AUTOSAR XML (schema 4-2-1)
package /MICROSAR/Os_swc/DataTypes
  impl type TimeInMicrosecondsType: range raw 0..4294967295, implementation-data-type=uint32
  impl type CounterType: range raw 0..255, implementation-data-type=uint8, type-emitter=Os
package /MICROSAR/Os_swc/Interfaces
  client server interface Os_Service: is-service=true, service-kind=OPERATING-SYSTEM
    operation GetCounterValue: possible-error=[E_OK, E_OS_ID]  # This service reads the current count value of a counter (returning either the hardware timer ticks if counter is driven by hardware or the software ticks when user drives counter).
      arg Value: type=TimeInMicrosecondsType, direction=OUT
    operation GetElapsedValue: possible-error=[E_OK, E_OS_ID, E_OS_VALUE]  # This service gets the number of ticks between the current tick value and a previously read tick value.
      arg Value: type=TimeInMicrosecondsType, direction=INOUT
      arg ElapsedValue: type=TimeInMicrosecondsType, direction=OUT
    5 x error:
      E_OK: error-code=0
      E_OS_ACCESS: error-code=1
      E_OS_ID: error-code=3
      E_OS_STATE: error-code=7
      E_OS_VALUE: error-code=8
package /MICROSAR/Os_swc/ComponentTypes
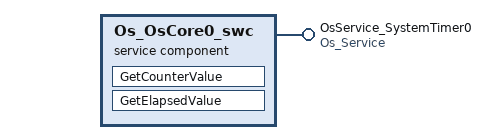
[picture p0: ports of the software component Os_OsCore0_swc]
  service sw component type Os_OsCore0_swc: category=SERVICE_COMPONENT
    provide port OsService_SystemTimer0: provided-interface=Os_Service
    behavior Os_OsCore0_swcInternalBehavior: handle-termination-and-restart=NO-SUPPORT, port-api-option{enable-take-address=true, indirect-api=false, port-defined-argument-value{value=SystemTimer0, value-type=CounterType}, port=OsService_SystemTimer0}
      operation invoked event OpEventGetCounterValue_GetCounterValue_OsService_SystemTimer0: start-on-event=Os_OsCore0_swcInternalBehavior/GetCounterValue, operation=OsService_SystemTimer0.GetCounterValue
      operation invoked event OpEventGetElapsedValue_GetElapsedValue_OsService_SystemTimer0: start-on-event=Os_OsCore0_swcInternalBehavior/GetElapsedValue, operation=OsService_SystemTimer0.GetElapsedValue
      runnable GetCounterValue: can-be-invoked-concurrently=true
      runnable GetElapsedValue: can-be-invoked-concurrently=true
  swc implementation Os_OsCore0_swcImplementation: programming-language=C, behavior=Os_OsCore0_swcInternalBehavior
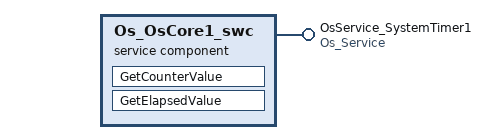
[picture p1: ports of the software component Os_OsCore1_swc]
  service sw component type Os_OsCore1_swc: category=SERVICE_COMPONENT
    provide port OsService_SystemTimer1: provided-interface=Os_Service
    behavior Os_OsCore1_swcInternalBehavior: handle-termination-and-restart=NO-SUPPORT, port-api-option{enable-take-address=true, indirect-api=false, port-defined-argument-value{value=SystemTimer1, value-type=CounterType}, port=OsService_SystemTimer1}
      operation invoked event OpEventGetCounterValue_GetCounterValue_OsService_SystemTimer1: start-on-event=Os_OsCore1_swcInternalBehavior/GetCounterValue, operation=OsService_SystemTimer1.GetCounterValue
      operation invoked event OpEventGetElapsedValue_GetElapsedValue_OsService_SystemTimer1: start-on-event=Os_OsCore1_swcInternalBehavior/GetElapsedValue, operation=OsService_SystemTimer1.GetElapsedValue
      runnable GetCounterValue: can-be-invoked-concurrently=true
      runnable GetElapsedValue: can-be-invoked-concurrently=true
  swc implementation Os_OsCore1_swcImplementation: programming-language=C, behavior=Os_OsCore1_swcInternalBehavior
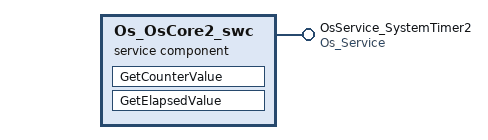
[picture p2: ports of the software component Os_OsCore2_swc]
  service sw component type Os_OsCore2_swc: category=SERVICE_COMPONENT
    provide port OsService_SystemTimer2: provided-interface=Os_Service
    behavior Os_OsCore2_swcInternalBehavior: handle-termination-and-restart=NO-SUPPORT, port-api-option{enable-take-address=true, indirect-api=false, port-defined-argument-value{value=SystemTimer2, value-type=CounterType}, port=OsService_SystemTimer2}
      operation invoked event OpEventGetCounterValue_GetCounterValue_OsService_SystemTimer2: start-on-event=Os_OsCore2_swcInternalBehavior/GetCounterValue, operation=OsService_SystemTimer2.GetCounterValue
      operation invoked event OpEventGetElapsedValue_GetElapsedValue_OsService_SystemTimer2: start-on-event=Os_OsCore2_swcInternalBehavior/GetElapsedValue, operation=OsService_SystemTimer2.GetElapsedValue
      runnable GetCounterValue: can-be-invoked-concurrently=true
      runnable GetElapsedValue: can-be-invoked-concurrently=true
  swc implementation Os_OsCore2_swcImplementation: programming-language=C, behavior=Os_OsCore2_swcInternalBehavior
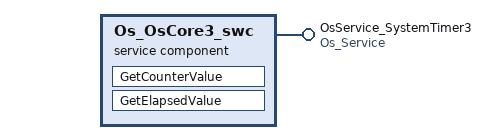
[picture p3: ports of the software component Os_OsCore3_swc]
  service sw component type Os_OsCore3_swc: category=SERVICE_COMPONENT
    provide port OsService_SystemTimer3: provided-interface=Os_Service
    behavior Os_OsCore3_swcInternalBehavior: handle-termination-and-restart=NO-SUPPORT, port-api-option{enable-take-address=true, indirect-api=false, port-defined-argument-value{value=SystemTimer3, value-type=CounterType}, port=OsService_SystemTimer3}
      operation invoked event OpEventGetCounterValue_GetCounterValue_OsService_SystemTimer3: start-on-event=Os_OsCore3_swcInternalBehavior/GetCounterValue, operation=OsService_SystemTimer3.GetCounterValue
      operation invoked event OpEventGetElapsedValue_GetElapsedValue_OsService_SystemTimer3: start-on-event=Os_OsCore3_swcInternalBehavior/GetElapsedValue, operation=OsService_SystemTimer3.GetElapsedValue
      runnable GetCounterValue: can-be-invoked-concurrently=true
      runnable GetElapsedValue: can-be-invoked-concurrently=true
  swc implementation Os_OsCore3_swcImplementation: programming-language=C, behavior=Os_OsCore3_swcInternalBehavior
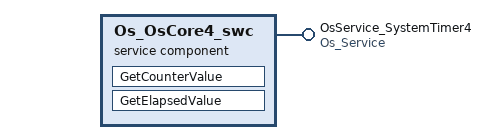
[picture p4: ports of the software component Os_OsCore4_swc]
  service sw component type Os_OsCore4_swc: category=SERVICE_COMPONENT
    provide port OsService_SystemTimer4: provided-interface=Os_Service
    behavior Os_OsCore4_swcInternalBehavior: handle-termination-and-restart=NO-SUPPORT, port-api-option{enable-take-address=true, indirect-api=false, port-defined-argument-value{value=SystemTimer4, value-type=CounterType}, port=OsService_SystemTimer4}
      operation invoked event OpEventGetCounterValue_GetCounterValue_OsService_SystemTimer4: start-on-event=Os_OsCore4_swcInternalBehavior/GetCounterValue, operation=OsService_SystemTimer4.GetCounterValue
      operation invoked event OpEventGetElapsedValue_GetElapsedValue_OsService_SystemTimer4: start-on-event=Os_OsCore4_swcInternalBehavior/GetElapsedValue, operation=OsService_SystemTimer4.GetElapsedValue
      runnable GetCounterValue: can-be-invoked-concurrently=true
      runnable GetElapsedValue: can-be-invoked-concurrently=true
  swc implementation Os_OsCore4_swcImplementation: programming-language=C, behavior=Os_OsCore4_swcInternalBehavior
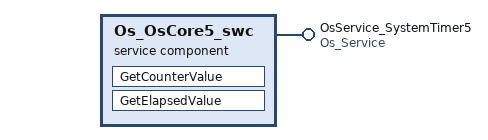
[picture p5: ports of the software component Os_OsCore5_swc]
  service sw component type Os_OsCore5_swc: category=SERVICE_COMPONENT
    provide port OsService_SystemTimer5: provided-interface=Os_Service
    behavior Os_OsCore5_swcInternalBehavior: handle-termination-and-restart=NO-SUPPORT, port-api-option{enable-take-address=true, indirect-api=false, port-defined-argument-value{value=SystemTimer5, value-type=CounterType}, port=OsService_SystemTimer5}
      operation invoked event OpEventGetCounterValue_GetCounterValue_OsService_SystemTimer5: start-on-event=Os_OsCore5_swcInternalBehavior/GetCounterValue, operation=OsService_SystemTimer5.GetCounterValue
      operation invoked event OpEventGetElapsedValue_GetElapsedValue_OsService_SystemTimer5: start-on-event=Os_OsCore5_swcInternalBehavior/GetElapsedValue, operation=OsService_SystemTimer5.GetElapsedValue
      runnable GetCounterValue: can-be-invoked-concurrently=true
      runnable GetElapsedValue: can-be-invoked-concurrently=true
  swc implementation Os_OsCore5_swcImplementation: programming-language=C, behavior=Os_OsCore5_swcInternalBehavior
